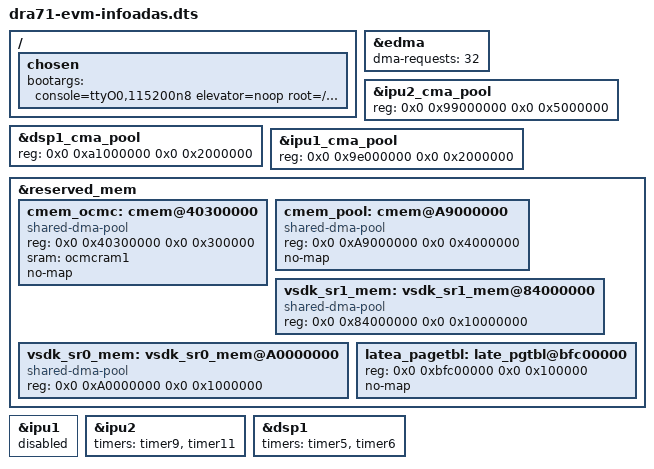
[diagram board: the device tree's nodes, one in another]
/*
 * Copyright (C) 2013 Texas Instruments Incorporated - http://www.ti.com/
 *
 * This program is free software; you can redistribute it and/or modify
 * it under the terms of the GNU General Public License version 2 as
 * published by the Free Software Foundation.
 */
#include "dra71-evm.dts"

#define DISABLE_PRCM(label) &label { ti,no-idle; ti,no-reset-on-init; }
#define DISABLE_COMPLETE(label) &label { status = "disabled"; ti,no-idle; ti,no-reset-on-init; }
#define LATE_ATTACH(label) &label { ti,late-attach; ti,no-idle; ti,no-reset-on-init; }

/ {
	chosen {
		bootargs = "console=ttyO0,115200n8 elevator=noop root=/dev/mmcblk1p2 rw rootwait earlyprintk fixrtc omapdrm.num_crtc=2 consoleblank=0 cma=64M rootfstype=ext4 snd.slots_reserved=1,1 loglevel=0 init=/home/root/init-demo.sh clk_ignore_unused";
	};
};

/* modules used by BIOS, disable from Linux */
DISABLE_COMPLETE(vip1);
DISABLE_COMPLETE(cal);
DISABLE_COMPLETE(i2c5);
DISABLE_COMPLETE(wdt2);
DISABLE_COMPLETE(vpe);
DISABLE_COMPLETE(ocmcram1);
DISABLE_COMPLETE(hdmi);
DISABLE_COMPLETE(hdmi0);
DISABLE_COMPLETE(dss);
DISABLE_COMPLETE(dispc);

/* modules shared between BIOS and Linux, Do not reset or cutoff clks */
DISABLE_PRCM(gpio1);
DISABLE_PRCM(gpio2);
DISABLE_PRCM(gpio4);
DISABLE_PRCM(gpio6);

/* Remote cores loaded by bootloader */
LATE_ATTACH(ipu1);
LATE_ATTACH(mmu_ipu1);
LATE_ATTACH(ipu2);
LATE_ATTACH(mmu_ipu2);
LATE_ATTACH(dsp1);
LATE_ATTACH(mmu0_dsp1);
LATE_ATTACH(mmu1_dsp1);

/* timers used by the remote cores */
LATE_ATTACH(timer3);
LATE_ATTACH(timer4);
LATE_ATTACH(timer5);
LATE_ATTACH(timer6);
LATE_ATTACH(timer7);
LATE_ATTACH(timer9);
LATE_ATTACH(timer11);
LATE_ATTACH(timer13);
LATE_ATTACH(timer14);
LATE_ATTACH(mailbox5);
LATE_ATTACH(mailbox6);
LATE_ATTACH(mailbox7);

/* Linux uses first 32 channels, BIOS uses last 32 */
&edma {
	dma-requests = <32>;
};

/* Update the CMA regions for Vision SDK binaries */
&ipu2_cma_pool {
	reg = <0x0 0x99000000 0x0 0x5000000>;
};

&dsp1_cma_pool {
	reg = <0x0 0xa1000000 0x0 0x2000000>;
};

&ipu1_cma_pool {
	reg = <0x0 0x9e000000 0x0 0x2000000>;
};


/* Additional memory regions required for Vision SDK
 * Keep this in sync with VSDK apps/build/tda2ex/mem_segment_definition_linux.xs
 */
&reserved_mem {
	cmem_ocmc: cmem@40300000 {
		compatible = "shared-dma-pool";
		reg = <0x0 0x40300000 0x0 0x300000>;
		sram = <&ocmcram1>;
		no-map;
		status = "okay";
	};

	cmem_pool: cmem@A9000000 {
		compatible = "shared-dma-pool";
		reg = <0x0 0xA9000000 0x0 0x4000000>;
		no-map;
		status = "okay";
	};

	vsdk_sr1_mem: vsdk_sr1_mem@84000000 {
		compatible = "shared-dma-pool";
		reg = <0x0 0x84000000 0x0 0x10000000>;
		status = "okay";
	};

	vsdk_sr0_mem: vsdk_sr0_mem@A0000000 {
		compatible = "shared-dma-pool";
		reg = <0x0 0xA0000000 0x0 0x1000000>;
		status = "okay";
	};

	/* Memory reserved for IOMMU table carveout in u-boot */
	latea_pagetbl: late_pgtbl@bfc00000 {
		reg = <0x0 0xbfc00000 0x0 0x100000>;
		no-map;
		status = "okay";
	};
};

&ipu1 {
	status= "disabled";
	/delete-property/ watchdog-timers;
};

&ipu2 {
	/delete-property/ watchdog-timers;
  timers= <&timer9> , <&timer11>;
};

&dsp1 {
	/delete-property/ watchdog-timers;
  timers= <&timer5> , <&timer6>;
};
